VERSION ""

NS_ :

BS_:

BU_: XXX EPS

CM_ "Toyota Prius 5th Gen TSS3 test DBC v1 from user logs";
CM_ "Based on observed CAN/CAN-FD frames from uploaded logs and Toyota reference naming.";

CM_ BO_ 48 "32-byte PT/body candidate frame";
CM_ BO_ 144 "32-byte PT/body candidate frame";
CM_ BO_ 201 "32-byte PT/body candidate frame";
CM_ BO_ 213 "8-byte status candidate frame";
CM_ BO_ 215 "32-byte PT/body candidate frame";
CM_ BO_ 277 "8-byte PT/body candidate frame";
CM_ BO_ 278 "8-byte PT/body candidate frame";
CM_ BO_ 295 "8-byte PT/body candidate frame";
CM_ BO_ 392 "64-byte CAN-FD TRACK_A candidate";
CM_ BO_ 393 "64-byte CAN-FD TRACK_A candidate";
CM_ BO_ 394 "64-byte CAN-FD TRACK_A candidate";
CM_ BO_ 395 "64-byte CAN-FD TRACK_A candidate";
CM_ BO_ 396 "48-byte CAN-FD TRACK_A candidate";
CM_ BO_ 416 "48-byte CAN-FD TRACK_B candidate";
CM_ BO_ 512 "64-byte CAN-FD object/status candidate";
CM_ BO_ 513 "64-byte CAN-FD object/status candidate";

BO_ 48 PT_STATE_0x030: 32 XXX
 SG_ PT030_B00 : 0|8@0+ (1,0) [0|255] "" XXX
 SG_ PT030_B01 : 8|8@0+ (1,0) [0|255] "" XXX
 SG_ PT030_B02 : 16|8@0+ (1,0) [0|255] "" XXX
 SG_ PT030_B03 : 24|8@0+ (1,0) [0|255] "" XXX
 SG_ PT030_B04 : 32|8@0+ (1,0) [0|255] "" XXX
 SG_ PT030_B05 : 40|8@0+ (1,0) [0|255] "" XXX
 SG_ PT030_B06 : 48|8@0+ (1,0) [0|255] "" XXX
 SG_ PT030_B07 : 56|8@0+ (1,0) [0|255] "" XXX
 SG_ PT030_B08 : 64|8@0+ (1,0) [0|255] "" XXX
 SG_ PT030_B09 : 72|8@0+ (1,0) [0|255] "" XXX
 SG_ PT030_B10 : 80|8@0+ (1,0) [0|255] "" XXX
 SG_ PT030_B11 : 88|8@0+ (1,0) [0|255] "" XXX
 SG_ PT030_B12 : 96|8@0+ (1,0) [0|255] "" XXX
 SG_ PT030_B13 : 104|8@0+ (1,0) [0|255] "" XXX
 SG_ PT030_B14 : 112|8@0+ (1,0) [0|255] "" XXX
 SG_ PT030_B15 : 120|8@0+ (1,0) [0|255] "" XXX
 SG_ PT030_B16 : 128|8@0+ (1,0) [0|255] "" XXX
 SG_ PT030_B17 : 136|8@0+ (1,0) [0|255] "" XXX
 SG_ PT030_B18 : 144|8@0+ (1,0) [0|255] "" XXX
 SG_ PT030_B19 : 152|8@0+ (1,0) [0|255] "" XXX
 SG_ PT030_B20 : 160|8@0+ (1,0) [0|255] "" XXX
 SG_ PT030_B21 : 168|8@0+ (1,0) [0|255] "" XXX
 SG_ PT030_B22 : 176|8@0+ (1,0) [0|255] "" XXX
 SG_ PT030_B23 : 184|8@0+ (1,0) [0|255] "" XXX
 SG_ PT030_B24 : 192|8@0+ (1,0) [0|255] "" XXX
 SG_ PT030_B25 : 200|8@0+ (1,0) [0|255] "" XXX
 SG_ PT030_B26 : 208|8@0+ (1,0) [0|255] "" XXX
 SG_ PT030_B27 : 216|8@0+ (1,0) [0|255] "" XXX
 SG_ PT030_TAIL : 224|32@0+ (1,0) [0|4294967295] "" XXX

BO_ 144 PT_STATE_0x090: 32 XXX
 SG_ PT090_B00 : 0|8@0+ (1,0) [0|255] "" XXX
 SG_ PT090_B01 : 8|8@0+ (1,0) [0|255] "" XXX
 SG_ PT090_B02 : 16|8@0+ (1,0) [0|255] "" XXX
 SG_ PT090_B03 : 24|8@0+ (1,0) [0|255] "" XXX
 SG_ PT090_B04 : 32|8@0+ (1,0) [0|255] "" XXX
 SG_ PT090_B05 : 40|8@0+ (1,0) [0|255] "" XXX
 SG_ PT090_B06 : 48|8@0+ (1,0) [0|255] "" XXX
 SG_ PT090_B07 : 56|8@0+ (1,0) [0|255] "" XXX
 SG_ PT090_B08 : 64|8@0+ (1,0) [0|255] "" XXX
 SG_ PT090_B09 : 72|8@0+ (1,0) [0|255] "" XXX
 SG_ PT090_B10 : 80|8@0+ (1,0) [0|255] "" XXX
 SG_ PT090_B11 : 88|8@0+ (1,0) [0|255] "" XXX
 SG_ PT090_B12 : 96|8@0+ (1,0) [0|255] "" XXX
 SG_ PT090_B13 : 104|8@0+ (1,0) [0|255] "" XXX
 SG_ PT090_B14 : 112|8@0+ (1,0) [0|255] "" XXX
 SG_ PT090_B15 : 120|8@0+ (1,0) [0|255] "" XXX
 SG_ PT090_B16 : 128|8@0+ (1,0) [0|255] "" XXX
 SG_ PT090_B17 : 136|8@0+ (1,0) [0|255] "" XXX
 SG_ PT090_B18 : 144|8@0+ (1,0) [0|255] "" XXX
 SG_ PT090_B19 : 152|8@0+ (1,0) [0|255] "" XXX
 SG_ PT090_B20 : 160|8@0+ (1,0) [0|255] "" XXX
 SG_ PT090_B21 : 168|8@0+ (1,0) [0|255] "" XXX
 SG_ PT090_B22 : 176|8@0+ (1,0) [0|255] "" XXX
 SG_ PT090_B23 : 184|8@0+ (1,0) [0|255] "" XXX
 SG_ PT090_B24 : 192|8@0+ (1,0) [0|255] "" XXX
 SG_ PT090_B25 : 200|8@0+ (1,0) [0|255] "" XXX
 SG_ PT090_B26 : 208|8@0+ (1,0) [0|255] "" XXX
 SG_ PT090_B27 : 216|8@0+ (1,0) [0|255] "" XXX
 SG_ PT090_TAIL : 224|32@0+ (1,0) [0|4294967295] "" XXX

BO_ 201 PT_STATE_0x0C9: 32 XXX
 SG_ PT0C9_B00 : 0|8@0+ (1,0) [0|255] "" XXX
 SG_ PT0C9_B01 : 8|8@0+ (1,0) [0|255] "" XXX
 SG_ PT0C9_B02 : 16|8@0+ (1,0) [0|255] "" XXX
 SG_ PT0C9_B03 : 24|8@0+ (1,0) [0|255] "" XXX
 SG_ PT0C9_B04 : 32|8@0+ (1,0) [0|255] "" XXX
 SG_ PT0C9_B05 : 40|8@0+ (1,0) [0|255] "" XXX
 SG_ PT0C9_B06 : 48|8@0+ (1,0) [0|255] "" XXX
 SG_ PT0C9_B07 : 56|8@0+ (1,0) [0|255] "" XXX
 SG_ PT0C9_B08 : 64|8@0+ (1,0) [0|255] "" XXX
 SG_ PT0C9_B09 : 72|8@0+ (1,0) [0|255] "" XXX
 SG_ PT0C9_B10 : 80|8@0+ (1,0) [0|255] "" XXX
 SG_ PT0C9_B11 : 88|8@0+ (1,0) [0|255] "" XXX
 SG_ PT0C9_B12 : 96|8@0+ (1,0) [0|255] "" XXX
 SG_ PT0C9_B13 : 104|8@0+ (1,0) [0|255] "" XXX
 SG_ PT0C9_B14 : 112|8@0+ (1,0) [0|255] "" XXX
 SG_ PT0C9_B15 : 120|8@0+ (1,0) [0|255] "" XXX
 SG_ PT0C9_B16 : 128|8@0+ (1,0) [0|255] "" XXX
 SG_ PT0C9_B17 : 136|8@0+ (1,0) [0|255] "" XXX
 SG_ PT0C9_B18 : 144|8@0+ (1,0) [0|255] "" XXX
 SG_ PT0C9_B19 : 152|8@0+ (1,0) [0|255] "" XXX
 SG_ PT0C9_B20 : 160|8@0+ (1,0) [0|255] "" XXX
 SG_ PT0C9_B21 : 168|8@0+ (1,0) [0|255] "" XXX
 SG_ PT0C9_B22 : 176|8@0+ (1,0) [0|255] "" XXX
 SG_ PT0C9_B23 : 184|8@0+ (1,0) [0|255] "" XXX
 SG_ PT0C9_B24 : 192|8@0+ (1,0) [0|255] "" XXX
 SG_ PT0C9_B25 : 200|8@0+ (1,0) [0|255] "" XXX
 SG_ PT0C9_B26 : 208|8@0+ (1,0) [0|255] "" XXX
 SG_ PT0C9_B27 : 216|8@0+ (1,0) [0|255] "" XXX
 SG_ PT0C9_TAIL : 224|32@0+ (1,0) [0|4294967295] "" XXX

BO_ 213 STATUS_0x0D5: 8 XXX
 SG_ ST0D5_B0 : 0|8@0+ (1,0) [0|255] "" XXX
 SG_ ST0D5_B1 : 8|8@0+ (1,0) [0|255] "" XXX
 SG_ ST0D5_B2 : 16|8@0+ (1,0) [0|255] "" XXX
 SG_ ST0D5_B3 : 24|8@0+ (1,0) [0|255] "" XXX
 SG_ ST0D5_B4 : 32|8@0+ (1,0) [0|255] "" XXX
 SG_ ST0D5_B5 : 40|8@0+ (1,0) [0|255] "" XXX
 SG_ ST0D5_B6 : 48|8@0+ (1,0) [0|255] "" XXX
 SG_ ST0D5_B7 : 56|8@0+ (1,0) [0|255] "" XXX

BO_ 215 PT_STATE_0x0D7: 32 XXX
 SG_ PT0D7_B00 : 0|8@0+ (1,0) [0|255] "" XXX
 SG_ PT0D7_B01 : 8|8@0+ (1,0) [0|255] "" XXX
 SG_ PT0D7_B02 : 16|8@0+ (1,0) [0|255] "" XXX
 SG_ PT0D7_B03 : 24|8@0+ (1,0) [0|255] "" XXX
 SG_ PT0D7_B04 : 32|8@0+ (1,0) [0|255] "" XXX
 SG_ PT0D7_B05 : 40|8@0+ (1,0) [0|255] "" XXX
 SG_ PT0D7_B06 : 48|8@0+ (1,0) [0|255] "" XXX
 SG_ PT0D7_B07 : 56|8@0+ (1,0) [0|255] "" XXX
 SG_ PT0D7_B08 : 64|8@0+ (1,0) [0|255] "" XXX
 SG_ PT0D7_B09 : 72|8@0+ (1,0) [0|255] "" XXX
 SG_ PT0D7_B10 : 80|8@0+ (1,0) [0|255] "" XXX
 SG_ PT0D7_B11 : 88|8@0+ (1,0) [0|255] "" XXX
 SG_ PT0D7_B12 : 96|8@0+ (1,0) [0|255] "" XXX
 SG_ PT0D7_B13 : 104|8@0+ (1,0) [0|255] "" XXX
 SG_ PT0D7_B14 : 112|8@0+ (1,0) [0|255] "" XXX
 SG_ PT0D7_B15 : 120|8@0+ (1,0) [0|255] "" XXX
 SG_ PT0D7_B16 : 128|8@0+ (1,0) [0|255] "" XXX
 SG_ PT0D7_B17 : 136|8@0+ (1,0) [0|255] "" XXX
 SG_ PT0D7_B18 : 144|8@0+ (1,0) [0|255] "" XXX
 SG_ PT0D7_B19 : 152|8@0+ (1,0) [0|255] "" XXX
 SG_ PT0D7_B20 : 160|8@0+ (1,0) [0|255] "" XXX
 SG_ PT0D7_B21 : 168|8@0+ (1,0) [0|255] "" XXX
 SG_ PT0D7_B22 : 176|8@0+ (1,0) [0|255] "" XXX
 SG_ PT0D7_B23 : 184|8@0+ (1,0) [0|255] "" XXX
 SG_ PT0D7_B24 : 192|8@0+ (1,0) [0|255] "" XXX
 SG_ PT0D7_B25 : 200|8@0+ (1,0) [0|255] "" XXX
 SG_ PT0D7_B26 : 208|8@0+ (1,0) [0|255] "" XXX
 SG_ PT0D7_B27 : 216|8@0+ (1,0) [0|255] "" XXX
 SG_ PT0D7_TAIL : 224|32@0+ (1,0) [0|4294967295] "" XXX

BO_ 277 PT_STATUS_0x115: 8 XXX
 SG_ PT115_B0 : 0|8@0+ (1,0) [0|255] "" XXX
 SG_ PT115_B1 : 8|8@0+ (1,0) [0|255] "" XXX
 SG_ PT115_B2 : 16|8@0+ (1,0) [0|255] "" XXX
 SG_ PT115_B3 : 24|8@0+ (1,0) [0|255] "" XXX
 SG_ PT115_B4 : 32|8@0+ (1,0) [0|255] "" XXX
 SG_ PT115_B5 : 40|8@0+ (1,0) [0|255] "" XXX
 SG_ PT115_B6 : 48|8@0+ (1,0) [0|255] "" XXX
 SG_ PT115_B7 : 56|8@0+ (1,0) [0|255] "" XXX

BO_ 278 PT_STATUS_0x116: 8 XXX
 SG_ PT116_B0 : 0|8@0+ (1,0) [0|255] "" XXX
 SG_ PT116_B1 : 8|8@0+ (1,0) [0|255] "" XXX
 SG_ PT116_B2 : 16|8@0+ (1,0) [0|255] "" XXX
 SG_ PT116_B3 : 24|8@0+ (1,0) [0|255] "" XXX
 SG_ PT116_B4 : 32|8@0+ (1,0) [0|255] "" XXX
 SG_ PT116_B5 : 40|8@0+ (1,0) [0|255] "" XXX
 SG_ PT116_B6 : 48|8@0+ (1,0) [0|255] "" XXX
 SG_ PT116_B7 : 56|8@0+ (1,0) [0|255] "" XXX

BO_ 295 PT_STATUS_0x127: 8 XXX
 SG_ PT127_B0 : 0|8@0+ (1,0) [0|255] "" XXX
 SG_ PT127_B1 : 8|8@0+ (1,0) [0|255] "" XXX
 SG_ PT127_B2 : 16|8@0+ (1,0) [0|255] "" XXX
 SG_ PT127_B3 : 24|8@0+ (1,0) [0|255] "" XXX
 SG_ PT127_B4 : 32|8@0+ (1,0) [0|255] "" XXX
 SG_ PT127_B5 : 40|8@0+ (1,0) [0|255] "" XXX
 SG_ PT127_B6 : 48|8@0+ (1,0) [0|255] "" XXX
 SG_ PT127_B7 : 56|8@0+ (1,0) [0|255] "" XXX

BO_ 392 TRACK_A_FD_8: 64 XXX
 SG_ TRK188_B00 : 0|8@0+ (1,0) [0|255] "" XXX
 SG_ TRK188_B01 : 8|8@0+ (1,0) [0|255] "" XXX
 SG_ TRK188_B02 : 16|8@0+ (1,0) [0|255] "" XXX
 SG_ TRK188_B03 : 24|8@0+ (1,0) [0|255] "" XXX
 SG_ TRK188_B04 : 32|8@0+ (1,0) [0|255] "" XXX
 SG_ TRK188_B05 : 40|8@0+ (1,0) [0|255] "" XXX
 SG_ TRK188_B06 : 48|8@0+ (1,0) [0|255] "" XXX
 SG_ TRK188_B07 : 56|8@0+ (1,0) [0|255] "" XXX
 SG_ TRK188_B08 : 64|8@0+ (1,0) [0|255] "" XXX
 SG_ TRK188_B09 : 72|8@0+ (1,0) [0|255] "" XXX
 SG_ TRK188_B10 : 80|8@0+ (1,0) [0|255] "" XXX
 SG_ TRK188_B11 : 88|8@0+ (1,0) [0|255] "" XXX
 SG_ TRK188_B12 : 96|8@0+ (1,0) [0|255] "" XXX
 SG_ TRK188_B13 : 104|8@0+ (1,0) [0|255] "" XXX
 SG_ TRK188_B14 : 112|8@0+ (1,0) [0|255] "" XXX
 SG_ TRK188_B15 : 120|8@0+ (1,0) [0|255] "" XXX
 SG_ TRK188_B16 : 128|8@0+ (1,0) [0|255] "" XXX
 SG_ TRK188_B17 : 136|8@0+ (1,0) [0|255] "" XXX
 SG_ TRK188_B18 : 144|8@0+ (1,0) [0|255] "" XXX
 SG_ TRK188_B19 : 152|8@0+ (1,0) [0|255] "" XXX
 SG_ TRK188_B20 : 160|8@0+ (1,0) [0|255] "" XXX
 SG_ TRK188_B21 : 168|8@0+ (1,0) [0|255] "" XXX
 SG_ TRK188_B22 : 176|8@0+ (1,0) [0|255] "" XXX
 SG_ TRK188_B23 : 184|8@0+ (1,0) [0|255] "" XXX
 SG_ TRK188_B24 : 192|8@0+ (1,0) [0|255] "" XXX
 SG_ TRK188_B25 : 200|8@0+ (1,0) [0|255] "" XXX
 SG_ TRK188_B26 : 208|8@0+ (1,0) [0|255] "" XXX
 SG_ TRK188_B27 : 216|8@0+ (1,0) [0|255] "" XXX
 SG_ TRK188_B28 : 224|8@0+ (1,0) [0|255] "" XXX
 SG_ TRK188_B29 : 232|8@0+ (1,0) [0|255] "" XXX
 SG_ TRK188_B30 : 240|8@0+ (1,0) [0|255] "" XXX
 SG_ TRK188_B31 : 248|8@0+ (1,0) [0|255] "" XXX
 SG_ TRK188_B32 : 256|8@0+ (1,0) [0|255] "" XXX
 SG_ TRK188_B33 : 264|8@0+ (1,0) [0|255] "" XXX
 SG_ TRK188_B34 : 272|8@0+ (1,0) [0|255] "" XXX
 SG_ TRK188_B35 : 280|8@0+ (1,0) [0|255] "" XXX
 SG_ TRK188_B36 : 288|8@0+ (1,0) [0|255] "" XXX
 SG_ TRK188_B37 : 296|8@0+ (1,0) [0|255] "" XXX
 SG_ TRK188_B38 : 304|8@0+ (1,0) [0|255] "" XXX
 SG_ TRK188_B39 : 312|8@0+ (1,0) [0|255] "" XXX
 SG_ TRK188_B40 : 320|8@0+ (1,0) [0|255] "" XXX
 SG_ TRK188_B41 : 328|8@0+ (1,0) [0|255] "" XXX
 SG_ TRK188_B42 : 336|8@0+ (1,0) [0|255] "" XXX
 SG_ TRK188_B43 : 344|8@0+ (1,0) [0|255] "" XXX
 SG_ TRK188_B44 : 352|8@0+ (1,0) [0|255] "" XXX
 SG_ TRK188_B45 : 360|8@0+ (1,0) [0|255] "" XXX
 SG_ TRK188_B46 : 368|8@0+ (1,0) [0|255] "" XXX
 SG_ TRK188_B47 : 376|8@0+ (1,0) [0|255] "" XXX
 SG_ TRK188_B48 : 384|8@0+ (1,0) [0|255] "" XXX
 SG_ TRK188_B49 : 392|8@0+ (1,0) [0|255] "" XXX
 SG_ TRK188_B50 : 400|8@0+ (1,0) [0|255] "" XXX
 SG_ TRK188_B51 : 408|8@0+ (1,0) [0|255] "" XXX
 SG_ TRK188_B52 : 416|8@0+ (1,0) [0|255] "" XXX
 SG_ TRK188_B53 : 424|8@0+ (1,0) [0|255] "" XXX
 SG_ TRK188_B54 : 432|8@0+ (1,0) [0|255] "" XXX
 SG_ TRK188_B55 : 440|8@0+ (1,0) [0|255] "" XXX
 SG_ TRK188_B56 : 448|8@0+ (1,0) [0|255] "" XXX
 SG_ TRK188_B57 : 456|8@0+ (1,0) [0|255] "" XXX
 SG_ TRK188_B58 : 464|8@0+ (1,0) [0|255] "" XXX
 SG_ TRK188_B59 : 472|8@0+ (1,0) [0|255] "" XXX
 SG_ TRK188_TAIL : 480|32@1+ (1,0) [0|4294967295] "" XXX

BO_ 393 TRACK_A_FD_9: 64 XXX
 SG_ TRK189_PAYLOAD : 0|480@0+ (1,0) [0|0] "" XXX
 SG_ TRK189_TAIL : 480|32@1+ (1,0) [0|4294967295] "" XXX

BO_ 394 TRACK_A_FD_10: 64 XXX
 SG_ TRK18A_PAYLOAD : 0|480@0+ (1,0) [0|0] "" XXX
 SG_ TRK18A_TAIL : 480|32@1+ (1,0) [0|4294967295] "" XXX

BO_ 395 TRACK_A_FD_11: 64 XXX
 SG_ TRK18B_PAYLOAD : 0|480@0+ (1,0) [0|0] "" XXX
 SG_ TRK18B_TAIL : 480|32@1+ (1,0) [0|4294967295] "" XXX

BO_ 396 TRACK_A_FD_12: 48 XXX
 SG_ TRK18C_PAYLOAD : 0|352@0+ (1,0) [0|0] "" XXX
 SG_ TRK18C_TAIL : 352|32@0+ (1,0) [0|4294967295] "" XXX

BO_ 416 TRACK_B_FD_0: 48 XXX
 SG_ TRK1A0_PAYLOAD : 0|352@0+ (1,0) [0|0] "" XXX
 SG_ TRK1A0_TAIL : 352|32@0+ (1,0) [0|4294967295] "" XXX

BO_ 512 OBJECT_FD_0: 64 XXX
 SG_ OBJ200_PAYLOAD : 0|480@0+ (1,0) [0|0] "" XXX
 SG_ OBJ200_TAIL : 480|32@1+ (1,0) [0|4294967295] "" XXX

BO_ 513 OBJECT_FD_1: 64 XXX
 SG_ OBJ201_PAYLOAD : 0|480@0+ (1,0) [0|0] "" XXX
 SG_ OBJ201_TAIL : 480|32@1+ (1,0) [0|4294967295] "" XXX

BO_ 37 STEER_ANGLE_SENSOR: 32 XXX
 SG_ STEER_ANGLE : 3|12@0- (1.5,0) [-500|500] "deg" XXX
 SG_ STEER_FRACTION : 39|4@0- (0.1,0) [-0.7|0.7] "deg" XXX
 SG_ STEER_RATE : 35|12@0- (1,0) [-2000|2000] "deg/s" XXX

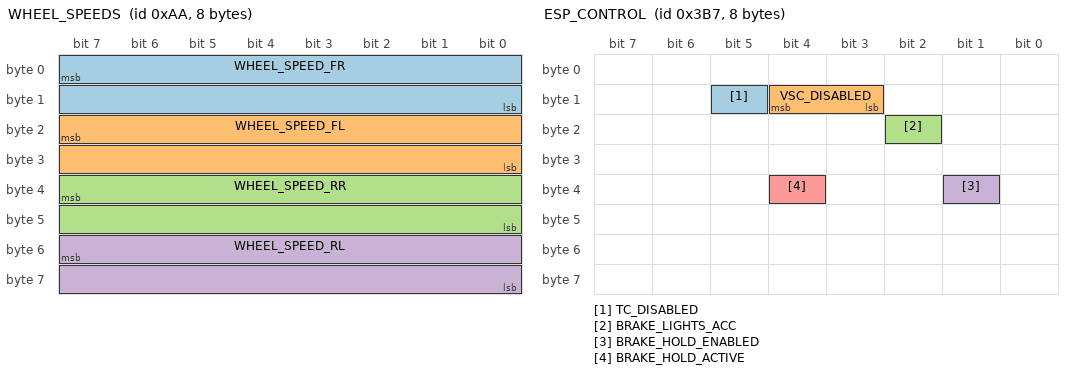
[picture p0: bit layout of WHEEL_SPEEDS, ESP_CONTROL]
BO_ 170 WHEEL_SPEEDS: 8 XXX
 SG_ WHEEL_SPEED_FR : 7|16@0+ (0.01,-67.67) [0|250] "km/h" XXX
 SG_ WHEEL_SPEED_FL : 23|16@0+ (0.01,-67.67) [0|250] "km/h" XXX
 SG_ WHEEL_SPEED_RR : 39|16@0+ (0.01,-67.67) [0|250] "km/h" XXX
 SG_ WHEEL_SPEED_RL : 55|16@0+ (0.01,-67.67) [0|250] "km/h" XXX

BO_ 951 ESP_CONTROL: 8 ESP
 SG_ TC_DISABLED : 13|1@0+ (1,0) [0|1] "" XXX
 SG_ VSC_DISABLED : 12|2@0+ (1,0) [0|1] "" XXX
 SG_ BRAKE_LIGHTS_ACC : 18|1@0+ (1,0) [0|1] "" XXX
 SG_ BRAKE_HOLD_ENABLED : 33|1@1+ (1,0) [0|1] "" XXX
 SG_ BRAKE_HOLD_ACTIVE : 36|1@0+ (1,0) [0|1] "" XXX

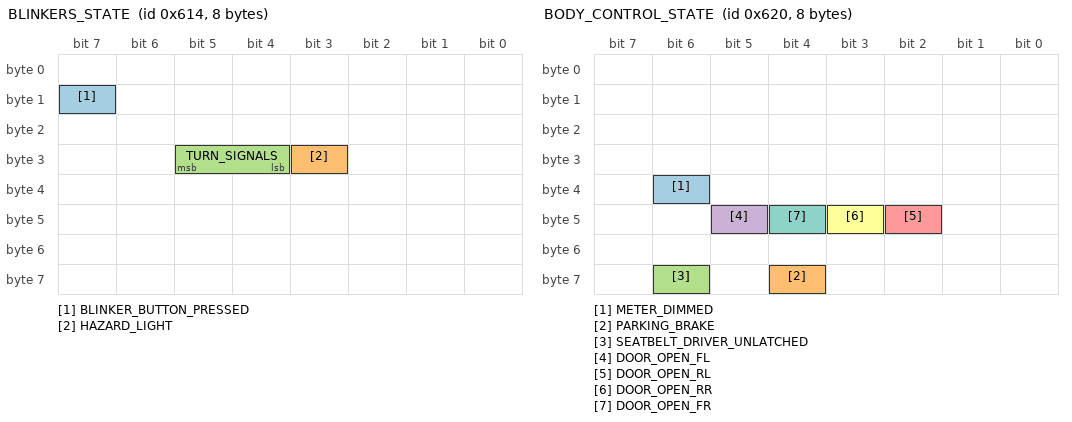
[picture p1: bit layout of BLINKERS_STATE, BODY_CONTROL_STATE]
BO_ 1556 BLINKERS_STATE: 8 XXX
 SG_ BLINKER_BUTTON_PRESSED : 15|1@0+ (1,0) [0|1] "" XXX
 SG_ HAZARD_LIGHT : 27|1@0+ (1,0) [0|1] "" XXX
 SG_ TURN_SIGNALS : 29|2@0+ (1,0) [0|3] "" XXX

BO_ 1526 PCM_CRUISE_5TH: 8 XXX
 SG_ CRUISE_BYTE : 63|8@0+ (1,0) [0|255] "" XXX

BO_ 1557 PCM_CRUISE_5TH_2: 8 XXX
 SG_ SET_SPEED : 23|8@0+ (1,0) [0|255] "km/h" XXX
 SG_ MAIN_ON : 31|1@1+ (1,0) [0|1] "" XXX

BO_ 1568 BODY_CONTROL_STATE: 8 XXX
 SG_ METER_DIMMED : 38|1@0+ (1,0) [0|1] "" XXX
 SG_ PARKING_BRAKE : 60|1@0+ (1,0) [0|1] "" XXX
 SG_ SEATBELT_DRIVER_UNLATCHED : 62|1@0+ (1,0) [0|1] "" XXX
 SG_ DOOR_OPEN_FL : 45|1@0+ (1,0) [0|1] "" XXX
 SG_ DOOR_OPEN_RL : 42|1@0+ (1,0) [0|1] "" XXX
 SG_ DOOR_OPEN_RR : 43|1@0+ (1,0) [0|1] "" XXX
 SG_ DOOR_OPEN_FR : 44|1@0+ (1,0) [0|1] "" XXX

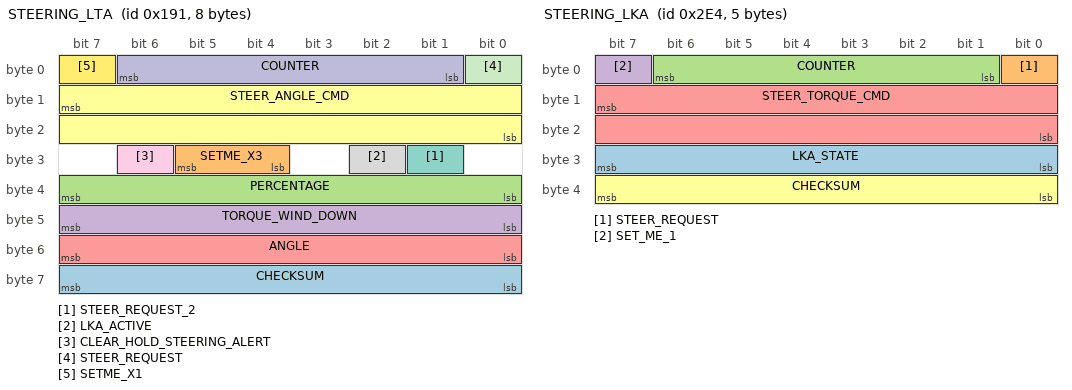
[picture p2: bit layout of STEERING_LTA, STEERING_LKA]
BO_ 401 STEERING_LTA: 8 XXX
 SG_ CHECKSUM : 63|8@0+ (1,0) [0|255] "" XXX
 SG_ SETME_X3 : 29|2@0+ (1,0) [0|3] "" XXX
 SG_ PERCENTAGE : 39|8@0+ (1,0) [0|255] "" XXX
 SG_ TORQUE_WIND_DOWN : 47|8@0+ (1,0) [0|255] "" XXX
 SG_ ANGLE : 55|8@0- (0.5,0) [0|255] "" XXX
 SG_ STEER_ANGLE_CMD : 15|16@0- (0.0573,0) [-540|540] "" XXX
 SG_ STEER_REQUEST_2 : 25|1@0+ (1,0) [0|1] "" XXX
 SG_ LKA_ACTIVE : 26|1@0+ (1,0) [0|1] "" XXX
 SG_ CLEAR_HOLD_STEERING_ALERT : 30|1@0+ (1,0) [0|1] "" XXX
 SG_ COUNTER : 6|6@0+ (1,0) [0|255] "" XXX
 SG_ STEER_REQUEST : 0|1@0+ (1,0) [0|1] "" XXX
 SG_ SETME_X1 : 7|1@0+ (1,0) [0|1] "" XXX

BO_ 740 STEERING_LKA: 5 XXX
 SG_ LKA_STATE : 31|8@0+ (1,0) [0|255] "" XXX
 SG_ STEER_REQUEST : 0|1@0+ (1,0) [0|1] "" XXX
 SG_ COUNTER : 6|6@0+ (1,0) [0|63] "" XXX
 SG_ SET_ME_1 : 7|1@0+ (1,0) [0|1] "" XXX
 SG_ STEER_TORQUE_CMD : 15|16@0- (1,0) [0|65535] "" XXX
 SG_ CHECKSUM : 39|8@0+ (1,0) [0|255] "" XXX

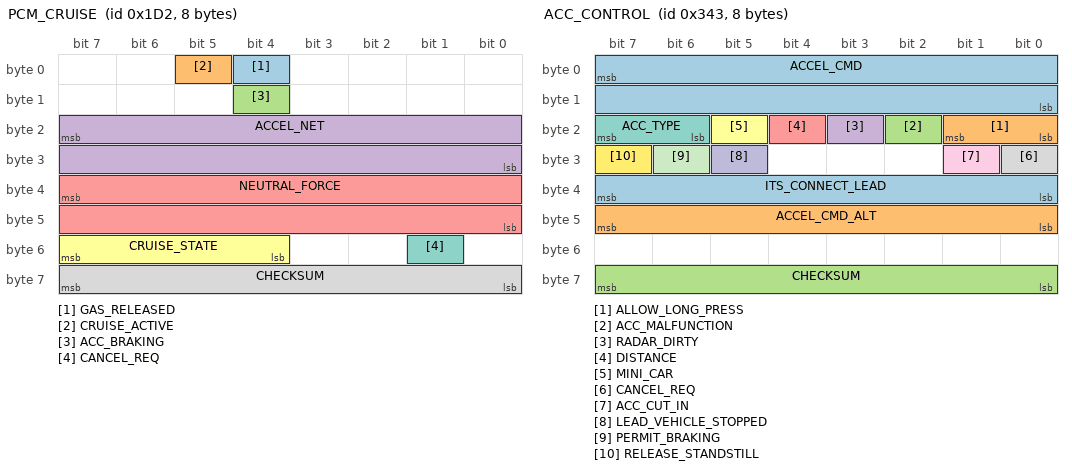
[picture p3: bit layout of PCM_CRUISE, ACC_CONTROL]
BO_ 466 PCM_CRUISE: 8 XXX
 SG_ GAS_RELEASED : 4|1@0+ (1,0) [0|1] "" XXX
 SG_ CRUISE_ACTIVE : 5|1@0+ (1,0) [0|1] "" XXX
 SG_ ACC_BRAKING : 12|1@0+ (1,0) [0|1] "" XXX
 SG_ ACCEL_NET : 23|16@0- (0.0009765625,0) [-20|20] "m/s^2" XXX
 SG_ NEUTRAL_FORCE : 39|16@0- (2,0) [-65536|65534] "N" XXX
 SG_ CRUISE_STATE : 55|4@0+ (1,0) [0|15] "" XXX
 SG_ CANCEL_REQ : 49|1@1+ (1,0) [0|1] "" XXX
 SG_ CHECKSUM : 63|8@0+ (1,0) [0|255] "" XXX

BO_ 835 ACC_CONTROL: 8 DSU
 SG_ ACCEL_CMD : 7|16@0- (0.001,0) [-20|20] "m/s^2" HCU
 SG_ ALLOW_LONG_PRESS : 17|2@0+ (1,0) [0|2] "" XXX
 SG_ ACC_MALFUNCTION : 18|1@0+ (1,0) [0|0] "" XXX
 SG_ RADAR_DIRTY : 19|1@0+ (1,0) [0|1] "" XXX
 SG_ DISTANCE : 20|1@0+ (1,0) [0|1] "" XXX
 SG_ MINI_CAR : 21|1@0+ (1,0) [0|1] "" XXX
 SG_ ACC_TYPE : 23|2@0+ (1,0) [0|3] "" HCU
 SG_ CANCEL_REQ : 24|1@0+ (1,0) [0|1] "" HCU
 SG_ ACC_CUT_IN : 25|1@0+ (1,0) [0|1] "" XXX
 SG_ LEAD_VEHICLE_STOPPED : 29|1@0+ (1,0) [0|0] "" DSU
 SG_ PERMIT_BRAKING : 30|1@0+ (1,0) [0|1] "" HCU
 SG_ RELEASE_STANDSTILL : 31|1@0+ (1,0) [0|1] "" HCU
 SG_ ITS_CONNECT_LEAD : 39|8@0+ (1,0) [0|1] "" Vector__XXX
 SG_ ACCEL_CMD_ALT : 47|8@0- (0.05,0) [0|0] "m/s^2" XXX
 SG_ CHECKSUM : 63|8@0+ (1,0) [0|255] "" XXX

BO_ 1042 LKAS_HUD: 8 DSU
 SG_ BARRIERS : 1|2@0+ (1,0) [0|3] "" XXX
 SG_ RIGHT_LINE : 3|2@0+ (1,0) [0|3] "" XXX
 SG_ LEFT_LINE : 5|2@0+ (1,0) [0|3] "" XXX
 SG_ LKAS_STATUS : 7|2@0+ (1,0) [0|3] "" XXX
 SG_ LDA_ALERT : 9|2@0+ (1,0) [0|3] "" XXX
 SG_ LDW_EXIST : 10|1@0+ (1,0) [0|1] "" XXX
 SG_ TWO_BEEPS : 12|1@0+ (1,0) [0|1] "" XXX
 SG_ ADJUSTING_CAMERA : 13|1@0+ (1,0) [0|1] "" XXX
 SG_ LDA_UNAVAILABLE_QUIET : 14|1@0+ (1,0) [0|1] "" XXX
 SG_ LDA_MALFUNCTION : 15|1@0+ (1,0) [0|1] "" XXX
 SG_ LDA_UNAVAILABLE : 16|1@0+ (1,0) [0|1] "" XXX
 SG_ LDA_SENSITIVITY : 18|2@0+ (1,0) [0|3] "" XXX
 SG_ LDA_SA_TOGGLE : 20|2@0+ (1,0) [0|3] "" XXX
 SG_ LDA_MESSAGES : 23|3@0+ (1,0) [0|1] "" XXX
 SG_ LDA_ON_MESSAGE : 31|2@0+ (1,0) [0|3] "" XXX
 SG_ REPEATED_BEEPS : 32|1@0+ (1,0) [0|1] "" XXX
 SG_ LANE_SWAY_TOGGLE : 43|1@0+ (1,0) [0|1] "" XXX
 SG_ LANE_SWAY_SENSITIVITY : 45|2@0+ (1,0) [0|3] "" XXX
 SG_ TAKE_CONTROL : 46|1@0+ (1,0) [0|1] "" XXX
 SG_ LDA_FRONT_CAMERA_BLOCKED : 47|1@0+ (1,0) [0|1] "" XXX
 SG_ LANE_SWAY_BUZZER : 50|2@0+ (1,0) [0|0] "" XXX
 SG_ LANE_SWAY_FLD : 53|3@0+ (1,0) [0|7] "" XXX
 SG_ LANE_SWAY_WARNING : 55|2@0+ (1,0) [0|3] "" XXX
 SG_ SET_ME_X01 : 42|1@0+ (1,0) [0|1] "" XXX
 SG_ SET_ME_X02 : 63|8@0+ (1,0) [0|1] "" XXX
